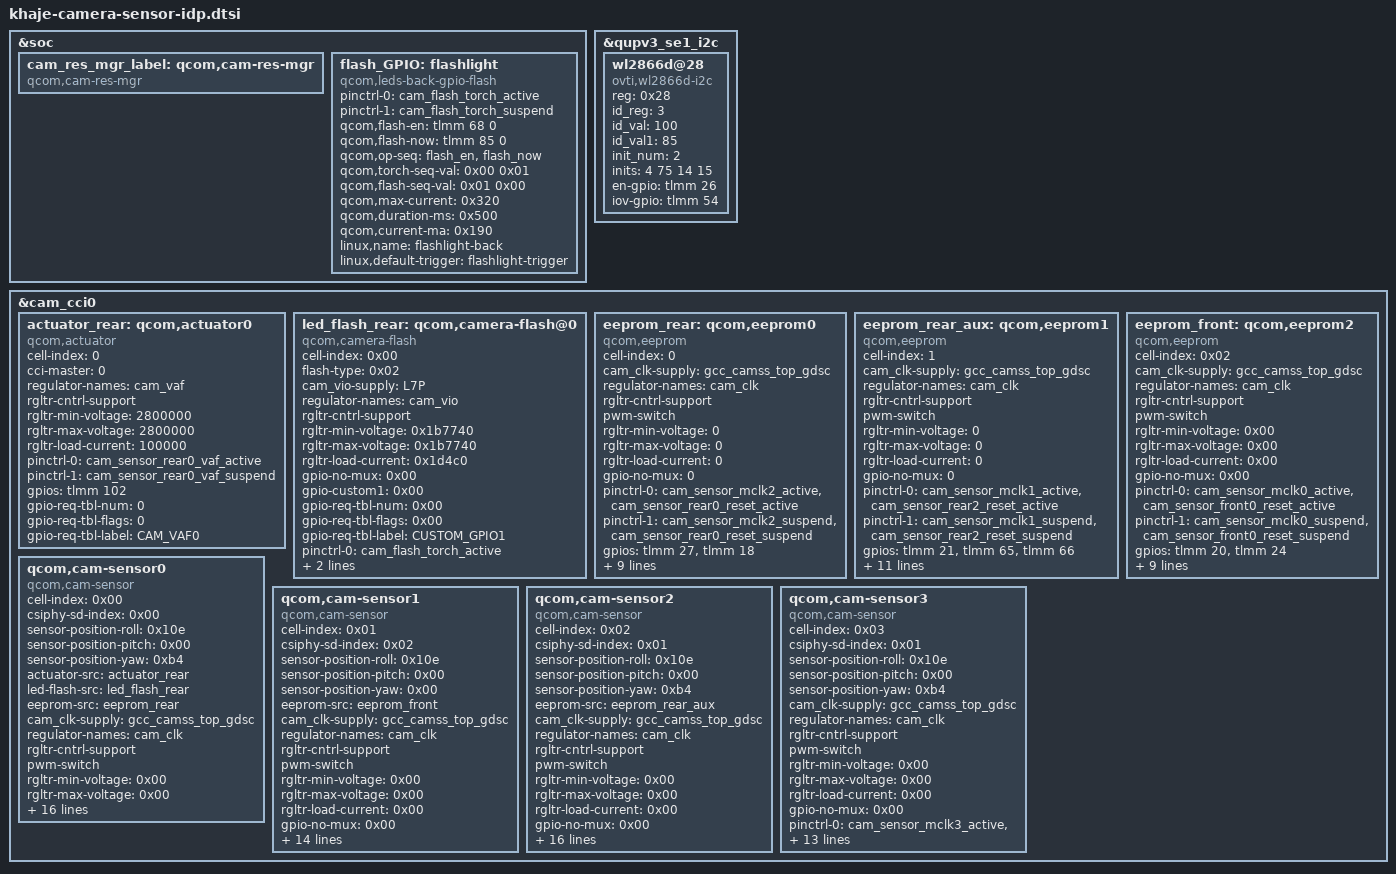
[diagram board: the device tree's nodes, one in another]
#include <dt-bindings/clock/qcom,gcc-khaje.h>
#include <dt-bindings/msm/msm-camera.h>

&soc {
	cam_res_mgr_label: qcom,cam-res-mgr {
		compatible = "qcom,cam-res-mgr";
		status = "ok";
	};
	
	flash_GPIO: flashlight {
		compatible = "qcom,leds-back-gpio-flash";
		status = "ok";
		pinctrl-names = "flash_default", "flash_sleep";
		pinctrl-0 = <&cam_flash_torch_active>;
		pinctrl-1 = <&cam_flash_torch_suspend>;
		qcom,flash-en = <&tlmm 68 0>;
		qcom,flash-now = <&tlmm 85 0>;
		qcom,op-seq = "flash_en", "flash_now";
		qcom,torch-seq-val = <0x00 0x01>;
		qcom,flash-seq-val = <0x01 0x00>;
		qcom,max-current = <0x320>;
		qcom,duration-ms = <0x500>;
		qcom,current-ma = <0x190>;
		linux,name = "flashlight-back";
		linux,default-trigger = "flashlight-trigger";
	};
};

&qupv3_se1_i2c {
	status = "ok";
	
	wl2866d@28 {
		compatible = "ovti,wl2866d-i2c";
		reg = <0x28>;
		id_reg = <3>;
		id_val = <100>;
		id_val1 = <85>;
		init_num = <2>;
		inits = <4 75 14 15>;
		en-gpio = <&tlmm 26 0>;
		iov-gpio = <&tlmm 54 0>;
		status = "ok";
	};
};

&cam_cci0 {
	actuator_rear: qcom,actuator0 {
		cell-index = <0>;
		compatible = "qcom,actuator";
		cci-master = <0>;
		regulator-names = "cam_vaf";
		rgltr-cntrl-support;
		rgltr-min-voltage = <2800000>;
		rgltr-max-voltage = <2800000>;
		rgltr-load-current = <100000>;
		pinctrl-names = "cam_default", "cam_suspend";
		pinctrl-0 = <&cam_sensor_rear0_vaf_active>;
		pinctrl-1 = <&cam_sensor_rear0_vaf_suspend>;
		gpios = <&tlmm 102 0>;
		gpio-req-tbl-num = <0>;
		gpio-req-tbl-flags = <0>;
		gpio-req-tbl-label = "CAM_VAF0";
		status = "ok";
	};
	
	led_flash_rear: qcom,camera-flash@0 {
		cell-index = <0x00>;
		compatible = "qcom,camera-flash";
		flash-type = <0x02>;
		cam_vio-supply = <&L7P>;
		regulator-names = "cam_vio";
		rgltr-cntrl-support;
		rgltr-min-voltage = <0x1b7740>;
		rgltr-max-voltage = <0x1b7740>;
		rgltr-load-current = <0x1d4c0>;
		gpio-no-mux = <0x00>;
		gpio-custom1 = <0x00>;
		gpio-req-tbl-num = <0x00>;
		gpio-req-tbl-flags = <0x00>;
		gpio-req-tbl-label = "CUSTOM_GPIO1";
		pinctrl-names = "cam_default", "cam_suspend";
		pinctrl-0 = <&cam_flash_torch_active>;
		pinctrl-1 = <&cam_flash_torch_suspend>;
		qcom,flash-gpios = <&tlmm 68 0>,
		<&tlmm 85 0>;
		status = "ok";
	};
	
	eeprom_rear: qcom,eeprom0 {
		cell-index = <0>;
		compatible = "qcom,eeprom";
		cam_clk-supply = <&gcc_camss_top_gdsc>;
		regulator-names = "cam_clk";
		rgltr-cntrl-support;
		pwm-switch;
		rgltr-min-voltage = <0>;
		rgltr-max-voltage = <0>;
		rgltr-load-current = <0>;
		gpio-no-mux = <0>;
		pinctrl-names = "cam_default", "cam_suspend";
		pinctrl-0 = <&cam_sensor_mclk2_active
		&cam_sensor_rear0_reset_active>;
		pinctrl-1 = <&cam_sensor_mclk2_suspend
		&cam_sensor_rear0_reset_suspend>;
		gpios = <&tlmm 27 0>,
		<&tlmm 18 0>;
		gpio-reset = <1>;
		gpio-req-tbl-num = <0 1>;
		gpio-req-tbl-flags = <1 0>;
		gpio-req-tbl-label = "CAMIF_MCLK2",
		"CAM_RESET0";
		sensor-mode = <0>;
		cci-master = <0>;
		status = "ok";
		clocks = <&gcc GCC_CAMSS_MCLK2_CLK>;
		clock-names = "cam_clk";
		clock-cntl-level = "turbo";
		clock-rates = <19200000>;
	};
	
	eeprom_rear_aux: qcom,eeprom1 {
		cell-index = <1>;
		compatible = "qcom,eeprom";
		cam_clk-supply = <&gcc_camss_top_gdsc>;
		regulator-names = "cam_clk";
		rgltr-cntrl-support;
		pwm-switch;
		rgltr-min-voltage = <0>;
		rgltr-max-voltage = <0>;
		rgltr-load-current = <0>;
		gpio-no-mux = <0>;
		pinctrl-names = "cam_default", "cam_suspend";
		pinctrl-0 = <&cam_sensor_mclk1_active &cam_sensor_rear2_reset_active>;
		pinctrl-1 = <&cam_sensor_mclk1_suspend &cam_sensor_rear2_reset_suspend>;
		gpios = <&tlmm 21 0>,
		<&tlmm 65 0>,
		<&tlmm 66 0>;
		gpio-reset = <0x01>;
		gpio-custom2 = <0x02>;
		gpio-req-tbl-num = <0x00 0x01 0x02>;
		gpio-req-tbl-flags = <0x01 0x00 0x00>;
		gpio-req-tbl-label = "CAMIF_MCLK1", "CAM_RESET2", "CAM_CUSTOM2";
		sensor-mode = <0x00>;
		cci-master = <0x01>;
		status = "ok";
		clocks = <&gcc GCC_CAMSS_MCLK1_CLK>;
		clock-names = "cam_clk";
		clock-cntl-level = "turbo";
		clock-rates = <19200000>;
	};
	
	eeprom_front: qcom,eeprom2 {
		cell-index = <0x02>;
		compatible = "qcom,eeprom";
		cam_clk-supply = <&gcc_camss_top_gdsc>;
		regulator-names = "cam_clk";
		rgltr-cntrl-support;
		pwm-switch;
		rgltr-min-voltage = <0x00>;
		rgltr-max-voltage = <0x00>;
		rgltr-load-current = <0x00>;
		gpio-no-mux = <0x00>;
		pinctrl-names = "cam_default", "cam_suspend";
		pinctrl-0 = <&cam_sensor_mclk0_active &cam_sensor_front0_reset_active>;
		pinctrl-1 = <&cam_sensor_mclk0_suspend &cam_sensor_front0_reset_suspend>;
		gpios = <&tlmm 20 0>,
		<&tlmm 24 0>;
		gpio-reset = <0x01>;
		gpio-req-tbl-num = <0x00 0x01>;
		gpio-req-tbl-flags = <0x01 0x00>;
		gpio-req-tbl-label = "CAMIF_MCLK0", "CAM_RESET1";
		sensor-mode = <0x00>;
		cci-master = <0x01>;
		status = "ok";
		clocks = <&gcc GCC_CAMSS_MCLK0_CLK>;
		clock-names = "cam_clk";
		clock-cntl-level = "turbo";
		clock-rates = <0x124f800>;
	};
	
	qcom,cam-sensor0 {
		cell-index = <0x00>;
		compatible = "qcom,cam-sensor";
		csiphy-sd-index = <0x00>;
		sensor-position-roll = <0x10e>;
		sensor-position-pitch = <0x00>;
		sensor-position-yaw = <0xb4>;
		actuator-src = <&actuator_rear>;
		led-flash-src = <&led_flash_rear>;
		eeprom-src = <&eeprom_rear>;
		cam_clk-supply = <&gcc_camss_top_gdsc>;
		regulator-names = "cam_clk";
		rgltr-cntrl-support;
		pwm-switch;
		rgltr-min-voltage = <0x00>;
		rgltr-max-voltage = <0x00>;
		rgltr-load-current = <0x00>;
		gpio-no-mux = <0x00>;
		pinctrl-names = "cam_default", "cam_suspend";
		pinctrl-0 = <&cam_sensor_mclk2_active &cam_sensor_rear0_reset_active>;
		pinctrl-1 = <&cam_sensor_mclk2_suspend &cam_sensor_rear0_reset_suspend>;
		gpios = <&tlmm 27 0>,
		<&tlmm 18 0>;
		gpio-reset = <0x01>;
		gpio-req-tbl-num = <0x00 0x01>;
		gpio-req-tbl-flags = <0x01 0x00>;
		gpio-req-tbl-label = "CAMIF_MCLK2", "CAM_RESET0";
		sensor-mode = <0x00>;
		cci-master = <0x00>;
		status = "ok";
		clocks = <&gcc GCC_CAMSS_MCLK2_CLK>;
		clock-names = "cam_clk";
		clock-cntl-level = "turbo";
		clock-rates = <0x124f800>;
	};
	
	/*Front*/
	qcom,cam-sensor1 {
		cell-index = <0x01>;
		compatible = "qcom,cam-sensor";
		csiphy-sd-index = <0x02>;
		sensor-position-roll = <0x10e>;
		sensor-position-pitch = <0x00>;
		sensor-position-yaw = <0x00>;
		eeprom-src = <&eeprom_front>;
		cam_clk-supply = <&gcc_camss_top_gdsc>;
		regulator-names = "cam_clk";
		rgltr-cntrl-support;
		pwm-switch;
		rgltr-min-voltage = <0x00>;
		rgltr-max-voltage = <0x00>;
		rgltr-load-current = <0x00>;
		gpio-no-mux = <0x00>;
		pinctrl-names = "cam_default", "cam_suspend";
		pinctrl-0 = <&cam_sensor_mclk0_active &cam_sensor_front0_reset_active>;
		pinctrl-1 = <&cam_sensor_mclk0_suspend &cam_sensor_front0_reset_suspend>;
		gpios = <&tlmm 20 0>,
		<&tlmm 24 0>;
		gpio-reset = <0x01>;
		gpio-req-tbl-num = <0x00 0x01>;
		gpio-req-tbl-flags = <0x01 0x00>;
		gpio-req-tbl-label = "CAMIF_MCLK0", "CAM_RESET1";
		sensor-mode = <0x00>;
		cci-master = <0x01>;
		status = "ok";
		clocks = <&gcc GCC_CAMSS_MCLK0_CLK>;
		clock-names = "cam_clk";
		clock-cntl-level = "turbo";
		clock-rates = <0x124f800>;
	};
	
	qcom,cam-sensor2 {
		cell-index = <0x02>;
		compatible = "qcom,cam-sensor";
		csiphy-sd-index = <0x01>;
		sensor-position-roll = <0x10e>;
		sensor-position-pitch = <0x00>;
		sensor-position-yaw = <0xb4>;
		eeprom-src = <&eeprom_rear_aux>;
		cam_clk-supply = <&gcc_camss_top_gdsc>;
		regulator-names = "cam_clk";
		rgltr-cntrl-support;
		pwm-switch;
		rgltr-min-voltage = <0x00>;
		rgltr-max-voltage = <0x00>;
		rgltr-load-current = <0x00>;
		gpio-no-mux = <0x00>;
		pinctrl-names = "cam_default", "cam_suspend";
		pinctrl-0 = <&cam_sensor_mclk1_active &cam_sensor_rear2_reset_active>;
		pinctrl-1 = <&cam_sensor_mclk1_suspend &cam_sensor_rear2_reset_suspend>;
		gpios = <&tlmm 21 0>,
		<&tlmm 65 0>,
		<&tlmm 66 0>;
		gpio-reset = <0x01>;
		gpio-custom2 = <0x02>;
		gpio-req-tbl-num = <0x00 0x01 0x02>;
		gpio-req-tbl-flags = <0x01 0x00 0x00>;
		gpio-req-tbl-label = "CAMIF_MCLK1", "CAM_RESET2", "CAM_CUSTOM2";
		sensor-mode = <0x00>;
		cci-master = <0x01>;
		status = "ok";
		clocks = <&gcc GCC_CAMSS_MCLK1_CLK>;
		clock-names = "cam_clk";
		clock-cntl-level = "turbo";
		clock-rates = <0x124f800>;
	};
	
	qcom,cam-sensor3 {
		cell-index = <0x03>;
		compatible = "qcom,cam-sensor";
		csiphy-sd-index = <0x01>;
		sensor-position-roll = <0x10e>;
		sensor-position-pitch = <0x00>;
		sensor-position-yaw = <0xb4>;
		cam_clk-supply = <&gcc_camss_top_gdsc>;
		regulator-names = "cam_clk";
		rgltr-cntrl-support;
		pwm-switch;
		rgltr-min-voltage = <0x00>;
		rgltr-max-voltage = <0x00>;
		rgltr-load-current = <0x00>;
		gpio-no-mux = <0x00>;
		pinctrl-names = "cam_default", "cam_suspend";
		pinctrl-0 = <&cam_sensor_mclk3_active &cam_sensor_rear2_reset_active>;
		pinctrl-1 = <&cam_sensor_mclk3_suspend &cam_sensor_rear2_reset_suspend>;
		gpios = <&tlmm 28 0>,
		<&tlmm 19 0>;
		gpio-reset = <0x01>;
		gpio-req-tbl-num = <0x00 0x01>;
		gpio-req-tbl-flags = <0x01 0x00>;
		gpio-req-tbl-label = "CAMIF_MCLK3", "CAM_RESET3";
		sensor-mode = <0x00>;
		cci-master = <0x00>;
		status = "ok";
		clocks = <&gcc GCC_CAMSS_MCLK3_CLK>;
		clock-names = "cam_clk";
		clock-cntl-level = "turbo";
		clock-rates = <0x124f800>;
	};
	
};
